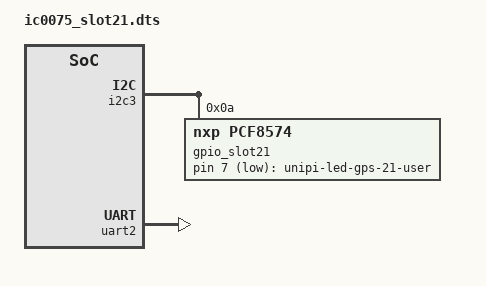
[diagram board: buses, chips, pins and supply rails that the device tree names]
/dts-v1/;


/plugin/;

/ {
	fragment@1 {
                target = <&i2c3>;  
                __overlay__ {
                        #address-cells = <1>;
                        #size-cells = <0>;
                        gpio_slot21: pca9501@10 {
                                compatible = "nxp,pcf8574";
                                gpio-controller;
                                #gpio-cells = <2>;
                                reg = <10>;
                                gpio-line-names = "GPS_nRST",
                                "GPS_extInt","","","","","","GPS_LED";
                        };
                };
	};

	fragment@3 {
		
		target = <&uart2>;
		__overlay__ {
			status = "okay";
		};

	};

	fragment@4 {
		target-path = "/";
		__overlay__ {
			gpsleds {
				compatible = "gpio-leds";
				gps-led@1 {
					label = "unipi-led-gps-21-user";
					gpios = <&gpio_slot21 7 1>;
					default-state = "off";
				};
			};
		};
	}; 

};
